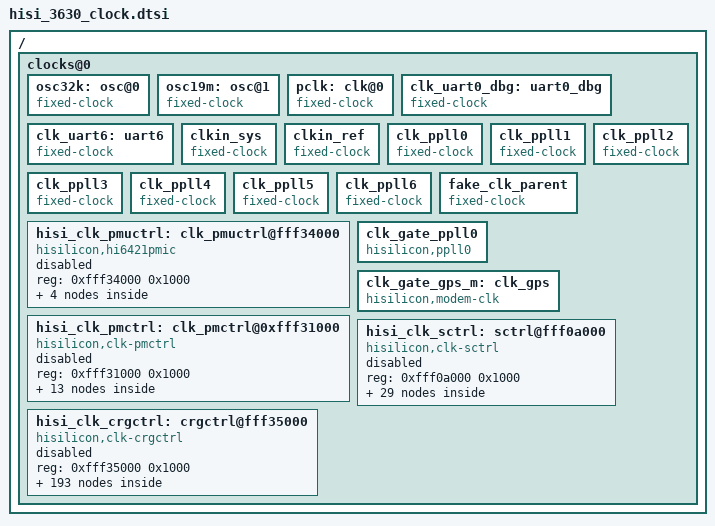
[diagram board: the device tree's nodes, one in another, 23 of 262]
/*
 * Hisilicon Ltd. Hi3630ASIC SoC
 *
 * Copyright (C) 2013 Hisilicon Technologies CO., Ltd.
 *
 * This program is free software; you can redistribute it and/or modify
 * it under the terms of the GNU General Public License version 2 as
 * publishhed by the Free Software Foundation.
 */
/ {
	clocks@0 {

		#address-cells = <1>;
		#size-cells = <1>;
		ranges;

		/*------------fixed clock---------------*/
		osc32k: osc@0 {
			compatible = "fixed-clock";
			#clock-cells = <0>;
			clock-frequency = <32768>;
			clock-output-names = "osc32khz";
		};

		osc19m: osc@1 {
			compatible = "fixed-clock";
			#clock-cells = <0>;
			clock-frequency = <19200000>;
			clock-output-names = "osc19mhz";
		};

		pclk: clk@0 {
			compatible = "fixed-clock";
			#clock-cells = <0>;
			clock-frequency = <20000000>;
			clock-output-names = "apb_pclk";
		};

		clk_uart0_dbg: uart0_dbg {
                        compatible = "fixed-clock";
                        #clock-cells = <0>;
                        clock-frequency = <19200000>;
                        clock-output-names = "uart0clk_dbg";
                };

		clk_uart6: uart6 {
			compatible = "fixed-clock";
			#clock-cells = <0>;
			clock-frequency = <19200000>;
			clock-output-names = "uart6clk";
		};

		clkin_sys: clkin_sys {
			compatible = "fixed-clock";
			#clock-cells = <0>;
			clock-frequency = <19200000>;
			clock-output-names = "clkin_sys";
		};

		clkin_ref: clkin_ref {
			compatible = "fixed-clock";
			#clock-cells = <0>;
			clock-frequency = <32768>;
			clock-output-names = "clkin_ref";
		};

		clk_ppll0: clk_ppll0 {
			compatible = "fixed-clock";
			#clock-cells = <0>;
			clock-frequency = <1440000000>;
			clock-output-names = "clk_ppll0";
		};

		clk_ppll1: clk_ppll1 {
			compatible = "fixed-clock";
			#clock-cells = <0>;
			clock-frequency = <1440000000>;
			clock-output-names = "clk_ppll1";
		};

		clk_ppll2: clk_ppll2 {
			compatible = "fixed-clock";
			#clock-cells = <0>;
			clock-frequency = <594000000>;
			clock-output-names = "clk_ppll2";
		};

		clk_ppll3: clk_ppll3 {
			compatible = "fixed-clock";
			#clock-cells = <0>;
			clock-frequency = <1600000000>;
			clock-output-names = "clk_ppll3";
		};

		clk_ppll4: clk_ppll4 {
			compatible = "fixed-clock";
			#clock-cells = <0>;
			clock-frequency = <667000000>;
			clock-output-names = "clk_ppll4";
		};

		clk_ppll5: clk_ppll5 {
			compatible = "fixed-clock";
			#clock-cells = <0>;
			clock-frequency = <420000000>;
			clock-output-names = "clk_ppll5";
		};

		clk_ppll6: clk_ppll6 {
			compatible = "fixed-clock";
			#clock-cells = <0>;
			clock-frequency = <491520000>;
			clock-output-names = "clk_ppll6";
		};

		fake_clk_parent: fake_clk_parent {
			compatible = "fixed-clock";
			#clock-cells = <0>;
			clock-frequency = <1000000>;
			clock-output-names = "fake_clk_parent";
		};

		hisi_clk_pmuctrl: clk_pmuctrl@fff34000 {
			compatible = "hisilicon,hi6421pmic";
			reg = <0xfff34000 0x1000>;
			status = "disabled";

			clk_pmu32ka: pmu32ka {
				compatible = "hisilicon,clk-gate";
				#clock-cells = <0>;
				pmu32khz;
				clocks = <&clkin_ref>;
				hisilicon,clkgate = <0xf0 0>;
				clock-output-names = "clk_pmu32ka";
			};

			clk_pmu32kb: pmu32kb {
				compatible = "hisilicon,clk-gate";
				#clock-cells = <0>;
				pmu32khz;
				clocks = <&clkin_ref>;
				hisilicon,clkgate = <0xf0 1>;
				clock-output-names = "clk_pmu32kb";
			};

			clk_pmu32kc: pmu32kc {
				compatible = "hisilicon,clk-gate";
				#clock-cells = <0>;
				pmu32khz;
				clocks = <&clkin_ref>;
				hisilicon,clkgate = <0xf0 2>;
				clock-output-names = "clk_pmu32kc";
			};

			clk_pmuaudioclk: clk_pmuaudioclk {
				compatible = "hisilicon,clk-gate";
				#clock-cells = <0>;
				pmu32khz;
				clocks = <&clkin_sys>;
				hisilicon,clkgate = <0xe6 7>;
				clock-output-names = "clk_pmuaudioclk";
			};

		};

		clk_gate_ppll0: clk_gate_ppll0 {
			compatible = "hisilicon,ppll0";
			#clock-cells = <0>;
			clocks = <&clk_ppll0>;
			hisilicon,ipc-lpm3-cmd = <0x000D0102 0x0>;
			clock-output-names = "clk_ap_ppll0";
		};

		clk_gate_gps_m:clk_gps {
			compatible = "hisilicon,modem-clk";
                        #clock-cells = <0>;
                        clocks = <&clkin_sys>;
			hisilicon,ipc-lpm3-cmd-en = <0x000D0002 0x7>;
			hisilicon,ipc-lpm3-cmd-dis = <0x000D0102 0x7>;
                        clock-output-names = "clk_gps";

		};

		hisi_clk_pmctrl: clk_pmctrl@0xfff31000 {
			compatible = "hisilicon,clk-pmctrl";
			reg = <0xfff31000 0x1000>;
			status = "disabled";

			clk_gate_ppll2: clk_gate_ppll2 {
				compatible = "hisilicon,ppll2";
				#clock-cells = <0>;
				clocks = <&clk_ppll2>;
				hisilicon,ppll2-powerdown = <0x40 0 26>;
				hisilicon,ppll2-gateen = <0x44 1 26>;
				clock-output-names = "clk_hdmi_ppll2";
			};

			/* A15 */
			clk_cluster0: clk_cluster0 {
				compatible = "hisilicon,hi3630-xfreq-clk";
				#clock-cells = <0>;
				hisilicon,get-rate-ipc-cmd = <0x0001020A 0x0>;
				hisilicon,set-rate-ipc-cmd = <0x0001030A 0x0>;
				/* <offset, mask_bits> */
				hisilicon,pll-sel = <0x164 0x3>;
				hisilicon,pll-div = <0x0 0x0 0x0 0x0>;
				hisilicon,hi3630-xfreq-devid = <0>;
				clock-output-names = "cpu-cluster.0";
			};

			/* A7 */
			clk_cluster1: clk_cluster1 {
				compatible = "hisilicon,hi3630-xfreq-clk";
				#clock-cells = <0>;
				hisilicon,get-rate-ipc-cmd = <0x0002020A 0x0>;
				hisilicon,set-rate-ipc-cmd = <0x0002030A 0x0>;
				/* <offset, mask_bits> */
				hisilicon,pll-sel = <0xA4 0x3>;
				hisilicon,pll-div = <0x0 0x0 0x0 0x0>;
				hisilicon,hi3630-xfreq-devid = <1>;
				clock-output-names = "cpu-cluster.1";
			};

			clk_g3d: clk_g3d {
				compatible = "hisilicon,hi3630-xfreq-clk";
				#clock-cells = <0>;
				hisilicon,get-rate-ipc-cmd = <0x0003020A 0x0>;
				hisilicon,set-rate-ipc-cmd = <0x0003030A 0x0>;
				/* <offset, mask_bits> */
				hisilicon,pll-sel = <0x0 0x0>;
				hisilicon,pll-div = <0x0 0x0 0x0 0x0>;
				hisilicon,hi3630-xfreq-devid = <2>;
				clock-output-names = "clk_g3d";
			};

			clk_ddrc_freq: clk_ddrc_freq {
				compatible = "hisilicon,hi3630-xfreq-clk";
				#clock-cells = <0>;
				hisilicon,get-rate-ipc-cmd = <0x0004020A 0x0>;
				hisilicon,set-rate-ipc-cmd = <0x00040309 0x0>;
				/* <offset, mask_bits> */
				hisilicon,pll-sel = <0x300 0xf0>;
				/* <offset ddrc_clk_divmask ddrc_aclk_divmask ddrc_busclk_divmask> */
				hisilicon,pll-div = <0x308 0x1f 0x60 0x180>;
				hisilicon,hi3630-xfreq-devid = <3>;
				clock-output-names = "clk_ddrc_freq";
			};

			clk_ddrc_min: clk_ddrc_min {
                                compatible = "hisilicon,hi3630-xfreq-clk";
                                #clock-cells = <0>;
                                hisilicon,get-rate-ipc-cmd = <0x0004020A 0x0>;
                                hisilicon,set-rate-ipc-cmd = <0x00040309 0x0>;
                                /* <offset, mask_bits> */
                                hisilicon,pll-sel = <0x300 0xf0>;
                                /* <offset ddrc_clk_divmask ddrc_aclk_divmask ddrc_busclk_divmask> */
                                hisilicon,pll-div = <0x308 0x1f 0x60 0x180>;
                                hisilicon,hi3630-xfreq-devid = <4>;
                                clock-output-names = "clk_ddrc_min";
                        };

			clk_ddrc_max: clk_ddrc_max {
				compatible = "hisilicon,hi3630-xfreq-clk";
				#clock-cells = <0>;
				hisilicon,get-rate-ipc-cmd = <0x0004020A 0x0>;
				hisilicon,set-rate-ipc-cmd = <0x00040308 0x0>;
				/* <offset, mask_bits> */
				hisilicon,pll-sel = <0x300 0xf0>;
				/* <offset ddrc_clk_divmask ddrc_aclk_divmask ddrc_busclk_divmask> */
				hisilicon,pll-div = <0x308 0x1f 0x60 0x180>;
				hisilicon,hi3630-xfreq-devid = <5>;
				clock-output-names = "clk_ddrc_max";
			};

			clk_xfreq_ppll1: clk_xfreq_ppll1 {
				compatible = "hisilicon,hi3630-xfreq-pll";
				#clock-cells = <0>;
				hisilicon,pll-ctrl-reg = <0x38>;
				clock-output-names = "ddrc_ppll1";
			};

			clk_xfreq_ppll2: clk_xfreq_ppll2 {
				compatible = "hisilicon,hi3630-xfreq-pll";
				#clock-cells = <0>;
				hisilicon,pll-ctrl-reg = <0x40>;
				clock-output-names = "ddrc_ppll2";
			};

			clk_xfreq_ppll3: clk_xfreq_ppll3 {
				compatible = "hisilicon,hi3630-xfreq-pll";
				#clock-cells = <0>;
				hisilicon,pll-ctrl-reg = <0x48>;
				clock-output-names = "ddrc_ppll3";
			};

			clk_xfreq_appll0: clk_xfreq_appll0 {
				compatible = "hisilicon,hi3630-xfreq-pll";
				#clock-cells = <0>;
				hisilicon,pll-ctrl-reg = <0x10>;
				clock-output-names = "clk_appll0";
			};

			clk_xfreq_appll1: clk_xfreq_appll1 {
				compatible = "hisilicon,hi3630-xfreq-pll";
				#clock-cells = <0>;
				hisilicon,pll-ctrl-reg = <0x18>;
				clock-output-names = "clk_appll1";
			};

			clk_xfreq_appll2: clk_xfreq_appll2 {
				compatible = "hisilicon,hi3630-xfreq-pll";
				#clock-cells = <0>;
				hisilicon,pll-ctrl-reg = <0x20>;
				clock-output-names = "clk_appll2";
			};
		};

		hisi_clk_sctrl: sctrl@fff0a000 {
			compatible = "hisilicon,clk-sctrl";
			reg = <0xfff0a000 0x1000>;
			status = "disabled";

			clk_xfreq_ppll0: clk_xfreq_ppll0 {
				compatible = "hisilicon,hi3630-xfreq-pll";
				#clock-cells = <0>;
				hisilicon,pll-ctrl-reg = <0x20>;
				clock-output-names = "ddrc_ppll0";
			};

			/*---------------------SYS TIMER CLOCK----------------------*/
			clk_gate_timclk0: clk_timclk0 {
				compatible = "hisilicon,hi3630-clk-gate";
				#clock-cells = <0>;
				clocks = <&clk_mux_timer0>;
				/* <0x0 0x0> reprents the enable reg is fake */
				hisilicon,hi3630-clkgate = <0x0 0x0>;
				clock-output-names = "clk_timclk0";
			};

			clk_gate_timclk1: clk_timclk1 {
				compatible = "hisilicon,hi3630-clk-gate";
				#clock-cells = <0>;
				clocks = <&clk_mux_timer1>;
				/* <0x0 0x0> reprents the enable reg is fake */
				hisilicon,hi3630-clkgate = <0x0 0x0>;
				clock-output-names = "clk_timclk1";
			};

			clk_gate_timclk2: clk_timclk2 {
				compatible = "hisilicon,hi3630-clk-gate";
				#clock-cells = <0>;
				clocks = <&clk_mux_timer2>;
				/* <0x0 0x0> reprents the enable reg is fake */
				hisilicon,hi3630-clkgate = <0x0 0x0>;
				clock-output-names = "clk_timclk2";
			};

			clk_gate_timclk3: clk_timclk3 {
				compatible = "hisilicon,hi3630-clk-gate";
				#clock-cells = <0>;
				clocks = <&clk_mux_timer3>;
				/* <0x0 0x0> reprents the enable reg is fake */
				hisilicon,hi3630-clkgate = <0x0 0x0>;
				clock-output-names = "clk_timclk3";
			};

			clk_mux_timer0: clk_mux_timer0 {
				compatible = "hisilicon,hi3630-clk-mux";
				#clock-cells = <0>;
				clocks = <&clkin_ref &clk_gate_timer01 &pclk &pclk>;
				hisilicon,clkmux-reg = <0 0x600>;
				clock-output-names = "clkmux_timer0";
			};

			clk_mux_timer1: clk_mux_timer1 {
				compatible = "hisilicon,hi3630-clk-mux";
				#clock-cells = <0>;
				clocks = <&clkin_ref &clk_gate_timer23 &pclk &pclk>;
				hisilicon,clkmux-reg = <0 0x1800>;
				clock-output-names = "clkmux_timer1";
			};

			clk_mux_timer2: clk_mux_timer2 {
				compatible = "hisilicon,hi3630-clk-mux";
				#clock-cells = <0>;
				clocks = <&clkin_ref &clk_gate_timer45 &pclk &pclk>;
				hisilicon,clkmux-reg = <0 0x6000>;
				clock-output-names = "clkmux_timer2";
			};

			clk_mux_timer3: clk_mux_timer3 {
				compatible = "hisilicon,hi3630-clk-mux";
				#clock-cells = <0>;
				clocks = <&clkin_ref &clk_gate_timer67 &pclk &pclk>;
				hisilicon,clkmux-reg = <0 0x18000>;
				clock-output-names = "clkmux_timer3";
			};

			clk_gate_timer01: clkgate@32 {
				compatible = "hisilicon,hi3630-clk-gate";
				#clock-cells = <0>;
				clocks = <&clk_factor_tcxo>;
				clock-output-names = "clk_timer01";
				hisilicon,hi3630-clkgate = <0x30 0x18>;
			};

			clk_gate_timer23: clkgate@33 {
				compatible = "hisilicon,hi3630-clk-gate";
				#clock-cells = <0>;
				clocks = <&clk_factor_tcxo>;
				clock-output-names = "clk_timer23";
				hisilicon,hi3630-clkgate = <0x30 0x60>;
			};

			clk_gate_timer45: clkgate@34 {
				compatible = "hisilicon,hi3630-clk-gate";
				#clock-cells = <0>;
				clocks = <&clk_factor_tcxo>;
				clock-output-names = "clk_timer45";
				hisilicon,hi3630-clkgate = <0x30 0x180>;
			};

			clk_gate_timer67: clkgate@35 {
				compatible = "hisilicon,hi3630-clk-gate";
				#clock-cells = <0>;
				clocks = <&clk_factor_tcxo>;
				clock-output-names = "clk_timer67";
				hisilicon,hi3630-clkgate = <0x30 0x600>;
			};

			clk_factor_tcxo: clk_factor_tcxo {
				compatible = "fixed-factor-clock";
				#clock-cells = <0>;
				clocks = <&clkin_sys>;
				/*mult, div*/
				clock-div = <4>;
				clock-mult = <1>;
				clock-output-names = "clk_factor_tcxo";
			};

			/*--------------------------AO GPIO--------------------------*/
			pclk_ao_gpio0: pclk_ao_gpio0 {
				compatible = "hisilicon,hi3630-clk-gate";
				#clock-cells = <0>;
				clocks = <&clk_div_aobus>;
				hisilicon,hi3630-clkgate = <0x30 0x800>;
				clock-output-names = "pclk_ao_gpio0";
			};

			pclk_ao_gpio1: pclk_ao_gpio1 {
				compatible = "hisilicon,hi3630-clk-gate";
				#clock-cells = <0>;
				clocks = <&clk_div_aobus>;
				hisilicon,hi3630-clkgate = <0x30 0x1000>;
				clock-output-names = "pclk_ao_gpio1";
			};

			pclk_ao_gpio2: pclk_ao_gpio2 {
				compatible = "hisilicon,hi3630-clk-gate";
				#clock-cells = <0>;
				clocks = <&clk_div_aobus>;
				hisilicon,hi3630-clkgate = <0x30 0x2000>;
				clock-output-names = "pclk_ao_gpio2";
			};

			pclk_ao_gpio3: pclk_ao_gpio3 {
				compatible = "hisilicon,hi3630-clk-gate";
				#clock-cells = <0>;
				clocks = <&clk_div_aobus>;
				hisilicon,hi3630-clkgate = <0x30 0x4000>;
				clock-output-names = "pclk_ao_gpio3";
			};

			pclk_ao_gpio4: pclk_ao_gpio4 {
				compatible = "hisilicon,hi3630-clk-gate";
				#clock-cells = <0>;
				clocks = <&clk_div_aobus>;
				hisilicon,hi3630-clkgate = <0x30 0x200000>;
				clock-output-names = "pclk_ao_gpio4";
			};

			pclk_ao_gpio5: pclk_ao_gpio5 {
				compatible = "hisilicon,hi3630-clk-gate";
				#clock-cells = <0>;
				clocks = <&clk_div_aobus>;
				hisilicon,hi3630-clkgate = <0x30 0x400000>;
				clock-output-names = "pclk_ao_gpio5";
			};

			/**/
			clk_div_aobus: clk_div_aobus {
				compatible = "hisilicon,hi3630-clk-div";
				#clock-cells = <0>;
				clocks = <&clk_gate_ppll0>;
				hisilicon,clkdiv-table = <64 1>;
				/*divider register offset, bits*/
				hisilicon,clkdiv = <0x104 0x3f>;
				clock-output-names = "clkdiv_aobus";
			};

			pclk_gate_rtc: pclk_rtc {
				compatible = "hisilicon,hi3630-clk-gate";
				#clock-cells = <0>;
				clocks = <&clk_div_aobus>;
				hisilicon,hi3630-clkgate = <0x30 0x2>;
				clock-output-names = "pclk_rtc";
			};

			/* follow timer clock to be another spare case,*/
			/*pclk_timer0: pclk_timer0 {
				compatible = "hisilicon,hi3630-clk-gate";
				#clock-cells = <0>;
				clocks = <&clk_div_aobus>;
				hisilicon,hi3630-clkgate = <0x30 0x8>;
				clock-output-names = "pclk_timer0";
			};*/

			/*clk_timer0: clk_timer0 {
				compatible = "hisilicon,hi3630-clk-gate";
				#clock-cells = <0>;
				clocks = <&clk_div_aobus>;
				hisilicon,hi3630-clkgate = <0x30 0x10>;
				clock-output-names = "clk_timer0";
				clock-friend-names = "pclk_timer0";
			};*/

			/*pclk_timer1: pclk_timer1 {
				compatible = "hisilicon,hi3630-clk-gate";
				#clock-cells = <0>;
				clocks = <&clk_div_aobus>;
				hisilicon,hi3630-clkgate = <0x30 0x20>;
				clock-output-names = "pclk_timer1";
			};*/

			/*clk_timer1: clk_timer1 {
				compatible = "hisilicon,hi3630-clk-gate";
				#clock-cells = <0>;
				clocks = <&clk_div_aobus>;
				hisilicon,hi3630-clkgate = <0x30 0x40>;
				clock-output-names = "clk_timer1";
				clock-friend-names = "pclk_timer1";
			};*/

			/*pclk_timer2: pclk_timer2 {
				compatible = "hisilicon,hi3630-clk-gate";
				#clock-cells = <0>;
				clocks = <&clk_div_aobus>;
				hisilicon,hi3630-clkgate = <0x30 0x80>;
				clock-output-names = "pclk_timer2";
			};*/

			/*clk_timer2: clk_timer2 {
				compatible = "hisilicon,hi3630-clk-gate";
				#clock-cells = <0>;
				clocks = <&clk_div_aobus>;
				hisilicon,hi3630-clkgate = <0x30 0x100>;
				clock-output-names = "clk_timer2";
			};*/

			/*pclk_timer3: pclk_timer3 {
				compatible = "hisilicon,hi3630-clk-gate";
				#clock-cells = <0>;
				clocks = <&clk_div_aobus>;
				hisilicon,hi3630-clkgate = <0x30 0x200>;
				clock-output-names = "pclk_timer3";
			};*/

			/*clk_timer3: clk_timer3 {
				compatible = "hisilicon,hi3630-clk-gate";
				#clock-cells = <0>;
				clocks = <&clk_div_aobus>;
				hisilicon,hi3630-clkgate = <0x30 0x400>;
				clock-output-names = "clk_timer3";
			};*/

			/**/
			clk_gate_out0: clk_gate_out0 {
				compatible = "hisilicon,hi3630-clk-gate";
				#clock-cells = <0>;
				clocks = <&clk_mux_clkout0>;
				hisilicon,hi3630-clkgate = <0x30 0x10000>;
				clock-output-names = "clk_out0";
			};

			clk_gate_out1: clk_gate_out1 {
				compatible = "hisilicon,hi3630-clk-gate";
				#clock-cells = <0>;
				clocks = <&clk_mux_clkout1>;
				hisilicon,hi3630-clkgate = <0x30 0x20000>;
				clock-output-names = "clk_out1";
			};

			clk_div_clkout0_tcxo: clkdiv_out0tcxo {
				compatible = "hisilicon,hi3630-clk-div";
				#clock-cells = <0>;
				clocks = <&clkin_sys>;
				hisilicon,clkdiv-table = <8 1>;
				/*divider register offset, bits*/
				hisilicon,clkdiv = <0x104 0x1c0>;
				clock-output-names = "clkdiv_out0tcxo";
			};

			clk_div_clkout1_tcxo: clkdiv_out1tcxo {
				compatible = "hisilicon,hi3630-clk-div";
				#clock-cells = <0>;
				clocks = <&clkin_sys>;
				hisilicon,clkdiv-table = <8 1>;
				hisilicon,clkdiv = <0x104 0xe00>;
				clock-output-names = "clkdiv_out1tcxo";
			};

			clk_mux_clkout0: clkmux_clkout0 {
				compatible = "hisilicon,hi3630-clk-mux";
				#clock-cells = <0>;
				hiword;
				clocks = <&clkin_ref &clk_div_clkout0_tcxo &clk_div_clkout0_pll &clk_div_clkout0_pll>;
				hisilicon,clkmux-reg = <0x104 0x3000>;
				clock-output-names = "clkmux_clkout0";
			};

			clk_mux_clkout1: clkmux_clkout1 {
				compatible = "hisilicon,hi3630-clk-mux";
				#clock-cells = <0>;
				hiword;
				clocks = <&clkin_ref &clk_div_clkout1_tcxo &clk_div_clkout1_pll &clk_div_clkout1_pll>;
				hisilicon,clkmux-reg = <0x104 0xc000>;
				clock-output-names = "clkmux_clkout1";
			};

			clk_gate_asp_tcxo: clk_asp_tcxo {
				compatible = "hisilicon,hi3630-clk-gate";
				#clock-cells = <0>;
				clocks = <&clkin_sys>;
				hisilicon,hi3630-clkgate = <0x30 0x8000000>;
				clock-output-names = "clk_asp_tcxo";
			};

		};
		hisi_clk_crgctrl: crgctrl@fff35000 {
			compatible = "hisilicon,clk-crgctrl";
			reg = <0xfff35000 0x1000>;
			status = "disabled";

			/*-----------------CRG TIMER CLOCK--------------------*/
			clk_gate_timclk4: clk_timclk4{
				compatible = "hisilicon,hi3630-clk-gate";
				#clock-cells = <0>;
				clocks = <&clk_mux_timer4>;
				/* <0x0 0x0> reprents the enable reg is fake */
				hisilicon,hi3630-clkgate = <0x0 0x0>;
				clock-output-names = "clk_timclk4";
			};

			clk_gate_timclk5: clk_timclk5{
				compatible = "hisilicon,hi3630-clk-gate";
				#clock-cells = <0>;
				clocks = <&clk_mux_timer5>;
				/* <0x0 0x0> reprents the enable reg is fake */
				hisilicon,hi3630-clkgate = <0x0 0x0>;
				clock-output-names = "clk_timclk5";
			};

			clk_gate_timclk6: clk_timclk6{
				compatible = "hisilicon,hi3630-clk-gate";
				#clock-cells = <0>;
				clocks = <&clk_mux_timer6>;
				/* <0x0 0x0> reprents the enable reg is fake */
				hisilicon,hi3630-clkgate = <0x0 0x0>;
				clock-output-names = "clk_timclk6";
			};

			clk_gate_timclk7: clk_timclk7{
				compatible = "hisilicon,hi3630-clk-gate";
				#clock-cells = <0>;
				clocks = <&clk_mux_timer7>;
				/* <0x0 0x0> reprents the enable reg is fake */
				hisilicon,hi3630-clkgate = <0x0 0x0>;
				clock-output-names = "clk_timclk7";
			};

			clk_mux_timer4: clk_mux_timer4 {
				compatible = "hisilicon,hi3630-clk-mux";
				#clock-cells = <0>;
				clocks = <&clkin_ref &clk_gate_timer89 &pclk &pclk>;
				hisilicon,clkmux-reg = <0x140 0x3>;
				clock-output-names = "clkmux_timer4";
			};

			clk_mux_timer5: clk_mux_timer5 {
				compatible = "hisilicon,hi3630-clk-mux";
				#clock-cells = <0>;
				clocks = <&clkin_ref &clk_gate_timer1011 &pclk &pclk>;
				hisilicon,clkmux-reg = <0x140 0xc>;
				clock-output-names = "clkmux_timer5";
			};

			clk_mux_timer6: clk_mux_timer6 {
				compatible = "hisilicon,hi3630-clk-mux";
				#clock-cells = <0>;
				clocks = <&clkin_ref &clk_gate_timer1213 &pclk &pclk>;
				hisilicon,clkmux-reg = <0x140 0x30>;
				clock-output-names = "clkmux_timer6";
			};

			clk_mux_timer7: clk_mux_timer7 {
				compatible = "hisilicon,hi3630-clk-mux";
				#clock-cells = <0>;
				clocks = <&clkin_ref &clk_gate_timer1415 &pclk &pclk>;
				hisilicon,clkmux-reg = <0x140 0xc0>;
				clock-output-names = "clkmux_timer7";
			};

			clk_gate_timer89: clkgate@36 {
				compatible = "hisilicon,hi3630-clk-gate";
				#clock-cells = <0>;
				clocks = <&clk_factor_tcxo>;
				clock-output-names = "clk_timer89";
				hisilicon,hi3630-clkgate = <0x10 0x400000>;
			};

			clk_gate_timer1011: clkgate@37 {
				compatible = "hisilicon,hi3630-clk-gate";
				#clock-cells = <0>;
				clocks = <&clk_factor_tcxo>;
				clock-output-names = "clk_timer1011";
				hisilicon,hi3630-clkgate = <0x10 0x800000>;
			};

			clk_gate_timer1213: clkgate@38 {
				compatible = "hisilicon,hi3630-clk-gate";
				#clock-cells = <0>;
				clocks = <&clk_factor_tcxo>;
				clock-output-names = "clk_timer1213";
				hisilicon,hi3630-clkgate = <0x10 0x1000000>;
			};

			clk_gate_timer1415: clkgate@39 {
				compatible = "hisilicon,hi3630-clk-gate";
				#clock-cells = <0>;
				clocks = <&clk_factor_tcxo>;
				clock-output-names = "clk_timer1415";
				hisilicon,hi3630-clkgate = <0x10 0x2000000>;
			};

			/*------------------------I2C CLOCK------------------------*/
			clk_gate_i2c0: clk_i2c0 {
				compatible = "hisilicon,hi3630-clk-gate";
				#clock-cells = <0>;
				clocks = <&clk_mux_i2c>;
				hisilicon,hi3630-clkgate = <0x20 0x10>;
				clock-output-names = "clk_i2c0";
			};

			clk_gate_i2c1: clk_i2c1 {
				compatible = "hisilicon,hi3630-clk-gate";
				#clock-cells = <0>;
				clocks = <&clk_mux_i2c>;
				hisilicon,hi3630-clkgate = <0x20 0x20>;
				clock-output-names = "clk_i2c1";
			};

			clk_gate_i2c2: clk_i2c2 {
				compatible = "hisilicon,hi3630-clk-gate";
				#clock-cells = <0>;
				clocks = <&clk_mux_i2c>;
				hisilicon,hi3630-clkgate = <0x20 0x40>;
				clock-output-names = "clk_i2c2";
			};

			clk_gate_i2c3: clk_i2c3 {
				compatible = "hisilicon,hi3630-clk-gate";
				#clock-cells = <0>;
				clocks = <&clk_mux_i2c>;
				hisilicon,hi3630-clkgate = <0x20 0x80>;
				clock-output-names = "clk_i2c3";
			};

			clk_gate_i2c4: clk_i2c4 {
				compatible = "hisilicon,hi3630-clk-gate";
				#clock-cells = <0>;
				clocks = <&clk_mux_i2c>;
				hisilicon,hi3630-clkgate = <0x20 0x8000000>;
				clock-output-names = "clk_i2c4";
			};

			clk_div_i2c: clkdiv_i2c {
				compatible = "hisilicon,hi3630-clk-div";
				#clock-cells = <0>;
				clocks = <&clk_div_hsic>;
				hisilicon,clkdiv-table = <16 1>;
				hisilicon,clkdiv = <0xe8 0xf0>;
				clock-output-names = "clkdiv_i2c";
			};

			clk_mux_i2c: clkmux_i2c {
				compatible = "hisilicon,hi3630-clk-mux";
				#clock-cells = <0>;
				hiword;
				clocks = <&clkin_sys &clk_div_i2c>;
				/*select register offset, mask*/
				hisilicon,clkmux-reg = <0xac 0x2000>;
				clock-output-names = "clkmux_i2c";
			};

			/*clk_andgt_i2c: clkgt_i2c {
				compatible = "hisilicon,clk-gate";
				#clock-cells = <0>;
				hiword;
				clocks = <&clk_div_hsic>;
				hisilicon,clkgate = <0xf8 0>;
				clock-output-names = "clkgt_i2c";
			};*/

			/*-------------------------SPI CLOCK----------------------*/
			clk_gate_spi0: clk_spi0 {
				compatible = "hisilicon,hi3630-clk-gate";
				#clock-cells = <0>;
				clocks = <&clk_mux_spi>;
				hisilicon,hi3630-clkgate = <0x20 0x100>;
				clock-output-names = "clk_spi0";
			};

			clk_gate_spi1: clk_gate_spi1 {
				compatible = "hisilicon,hi3630-clk-gate";
				#clock-cells = <0>;
				clocks = <&clk_mux_spi>;
				hisilicon,hi3630-clkgate = <0x20 0x200>;
				clock-output-names = "clk_spi1";
			};

			clk_mux_spi: clkmux_spi {
				compatible = "hisilicon,hi3630-clk-mux";
				#clock-cells = <0>;
				hiword;
				clocks = <&clkin_sys &clk_div_spi>;
				/*select register offset, mask*/
				hisilicon,clkmux-reg = <0xac 0x100>;
				clock-output-names = "clkmux_spi";
			};

			clk_div_spi: clk_div_spi {
				compatible = "hisilicon,hi3630-clk-div";
				#clock-cells = <0>;
				clocks = <&clk_andgt_spi>;
				hisilicon,clkdiv-table = <16 1>;
				hisilicon,clkdiv = <0xc4 0xf000>;
				clock-output-names = "clkdiv_spi";
			};

			clk_andgt_spi: clkgt_spi {
				compatible = "hisilicon,clk-gate";
				#clock-cells = <0>;
				hiword;
				clocks = <&clk_div_hsic>;
				/*enable register, enable bit*/
				hisilicon,clkgate = <0xf4 13>;
				clock-output-names = "clkgt_spi";
			};

			clk_div_hsic: clkdiv_hsic {
				compatible = "hisilicon,hi3630-clk-div";
				#clock-cells = <0>;
				clocks = <&clk_gate_ppll0>;
				hisilicon,clkdiv-table = <4 1>;
				hisilicon,clkdiv = <0xd4 0x180>;
				clock-output-names = "clkdiv_hsic";
			};

			/*clk_andgt_hsic: clkgt_hsic {
				compatible = "hisilicon,clk-gate";
				#clock-cells = <0>;
				hiword;
				clocks = <&clk_gate_ppll0>;
				hisilicon,clkgate = <0xf4 7>;
				clock-output-names = "clkgt_hsic";
			};*/

			/*-----------------------UART CLOCK-----------------------*/
			clk_gate_uart0: clk_uart0 {
				compatible = "hisilicon,hi3630-clk-gate";
				#clock-cells = <0>;
				clocks = <&clk_mux_uartl>;
				hisilicon,hi3630-clkgate = <0x20 0x400>;
				clock-output-names = "clk_uart0";
			};

			clk_gate_uart1: clk_uart1 {
				compatible = "hisilicon,hi3630-clk-gate";
				#clock-cells = <0>;
				clocks = <&clk_mux_uarth>;
				hisilicon,hi3630-clkgate = <0x20 0x800>;
				clock-output-names = "clk_uart1";
			};

			clk_gate_uart2: clk_uart2 {
				compatible = "hisilicon,hi3630-clk-gate";
				#clock-cells = <0>;
				clocks = <&clk_mux_uartl>;
				hisilicon,hi3630-clkgate = <0x20 0x1000>;
				clock-output-names = "clk_uart2";
			};

			clk_gate_uart3: clk_uart3 {
				compatible = "hisilicon,hi3630-clk-gate";
				#clock-cells = <0>;
				clocks = <&clk_mux_uartl>;
				hisilicon,hi3630-clkgate = <0x20 0x2000>;
				clock-output-names = "clk_uart3";
			};

			clk_gate_uart4: clk_uart4 {
				compatible = "hisilicon,hi3630-clk-gate";
				#clock-cells = <0>;
				clocks = <&clk_mux_uarth>;
				hisilicon,hi3630-clkgate = <0x20 0x4000>;
				clock-output-names = "clk_uart4";
			};

			clk_gate_uart5: clk_uart5 {
				compatible = "hisilicon,hi3630-clk-gate";
				#clock-cells = <0>;
				clocks = <&clk_mux_uartl>;
				hisilicon,hi3630-clkgate = <0x20 0x8000>;
				clock-output-names = "clk_uart5";
			};

			clk_mux_uartl: clkmux_uartl {
				compatible = "hisilicon,hi3630-clk-mux";
				#clock-cells = <0>;
				hiword;
				clocks = <&clkin_sys &clk_div_uartl>;
				/*select register offset, mask*/
				hisilicon,clkmux-reg = <0xac 0x4>;
				clock-output-names = "clkmux_uartl";
			};

			clk_mux_uarth: clkmux_uarth {
				compatible = "hisilicon,hi3630-clk-mux";
				#clock-cells = <0>;
				hiword;
				clocks = <&clkin_sys &clk_div_uarth>;
				/*select register offset, mask*/
				hisilicon,clkmux-reg = <0xac 0x8>;
				clock-output-names = "clkmux_uarth";
			};

			clk_div_uarth: clkdiv_uarth {
				compatible = "hisilicon,hi3630-clk-div";
				#clock-cells = <0>;
				clocks = <&clk_andgt_uarth>;
				hisilicon,clkdiv-table = <16 1>;
				hisilicon,clkdiv = <0xb0 0x780>;
				clock-output-names = "clkdiv_uarth";
			};

			clk_div_uartl: clkdiv_uartl {
				compatible = "hisilicon,hi3630-clk-div";
				#clock-cells = <0>;
				clocks = <&clk_andgt_uartl>;
				hisilicon,clkdiv-table = <16 1>;
				hisilicon,clkdiv = <0xb0 0x7800>;
				clock-output-names = "clkdiv_uartl";
			};

			clk_andgt_uarth: clkgt_uarth {
				compatible = "hisilicon,clk-gate";
				#clock-cells = <0>;
				hiword;
				clocks = <&clk_div_hsic>;
				/*enable register, enable bit*/
				hisilicon,clkgate = <0xf4 11>;
				clock-output-names = "clkgt_uarth";
			};

			clk_andgt_uartl: clkgt_uartl {
				compatible = "hisilicon,clk-gate";
				#clock-cells = <0>;
				hiword;
				clocks = <&clk_div_hsic>;
				/*enable register, enable bit*/
				hisilicon,clkgate = <0xf4 12>;
				clock-output-names = "clkgt_uartl";
			};

			/*-----------------------DMA CLOCK----------------------*/
			clk_gate_dmabus: clk_dmabus {
				compatible = "hisilicon,hi3630-clk-gate";
				#clock-cells = <0>;
				clocks = <&clk_div_dmabus>;
				hisilicon,hi3630-clkgate = <0x00 0x400000>;
				clock-output-names = "clk_dmabus";
			};

			clk_gate_dma2cfgbus: clk_dma2cfgbus {
				compatible = "hisilicon,hi3630-clk-gate";
				#clock-cells = <0>;
				clocks = <&clk_div_dmabus>;
				hisilicon,hi3630-clkgate = <0x00 0x800000>;
				clock-output-names = "clk_dma2cfgbus";
			};

			clk_gate_dmac: clk_dmac {
				compatible = "hisilicon,hi3630-clk-gate";
				#clock-cells = <0>;
				clocks = <&clk_div_dmabus>;
				hisilicon,hi3630-clkgate = <0x30 0x1>;
				clock-output-names = "clk_dmac";
			};

			clk_div_dmabus: clkdiv_dmabus {
				compatible = "hisilicon,hi3630-clk-div";
				#clock-cells = <0>;
				clocks = <&clk_div_sysbus>;
				hisilicon,clkdiv-table = <2 1>;
				hisilicon,clkdiv = <0xec 0x8000>;
				clock-output-names = "clkdiv_dmabus";
			};

			clk_div_sysbus: clkdiv_sysbus{
				compatible = "hisilicon,hi3630-clk-div";
				#clock-cells = <0>;
				clocks = <&clk_mux_sysbus>;
				hisilicon,clkdiv-table = <32 1>;
				/*divider register offset, bits*/
				hisilicon,clkdiv = <0xa8 0x1f>;
				clock-output-names = "clkdiv_sysbus";
			};

			clk_mux_sysbus: clkmux_sysbus {
				compatible = "hisilicon,hi3630-clk-mux";
				#clock-cells = <0>;
				hiword;
				clocks = <&clk_gate_ppll0 &clk_ppll1>;
				/*select register offset, mask*/
				hisilicon,clkmux-reg = <0xac 0x1>;
				clock-output-names = "clkmux_sysbus";
			};

			/*-----------------------------GPIO-------------------------*/
			pclk_gpio0: pclk_gpio0 {
				compatible = "hisilicon,hi3630-clk-gate";
				#clock-cells = <0>;
				clocks = <&clk_div_cfgbus>;
				hisilicon,hi3630-clkgate = <0x010 0x1>;
				clock-output-names = "pclk_gpio0";
			};

			pclk_gpio1: pclk_gpio1 {
				compatible = "hisilicon,hi3630-clk-gate";
				#clock-cells = <0>;
				clocks = <&clk_div_cfgbus>;
				hisilicon,hi3630-clkgate = <0x010 0x2>;
				clock-output-names = "pclk_gpio1";
			};

			pclk_gpio2: pclk_gpio2 {
				compatible = "hisilicon,hi3630-clk-gate";
				#clock-cells = <0>;
				clocks = <&clk_div_cfgbus>;
				hisilicon,hi3630-clkgate = <0x010 0x4>;
				clock-output-names = "pclk_gpio2";
			};

			pclk_gpio3: pclk_gpio3 {
				compatible = "hisilicon,hi3630-clk-gate";
				#clock-cells = <0>;
				clocks = <&clk_div_cfgbus>;
				hisilicon,hi3630-clkgate = <0x010 0x8>;
				clock-output-names = "pclk_gpio3";
			};

			pclk_gpio4: pclk_gpio4 {
				compatible = "hisilicon,hi3630-clk-gate";
				#clock-cells = <0>;
				clocks = <&clk_div_cfgbus>;
				hisilicon,hi3630-clkgate = <0x010 0x10>;
				clock-output-names = "pclk_gpio4";
			};

			pclk_gpio5: pclk_gpio5 {
				compatible = "hisilicon,hi3630-clk-gate";
				#clock-cells = <0>;
				clocks = <&clk_div_cfgbus>;
				hisilicon,hi3630-clkgate = <0x010 0x20>;
				clock-output-names = "pclk_gpio5";
			};

			pclk_gpio6: pclk_gpio6 {
				compatible = "hisilicon,hi3630-clk-gate";
				#clock-cells = <0>;
				clocks = <&clk_div_cfgbus>;
				hisilicon,hi3630-clkgate = <0x10 0x40>;
				clock-output-names = "pclk_gpio6";
			};

			pclk_gpio7: pclk_gpio7 {
				compatible = "hisilicon,hi3630-clk-gate";
				#clock-cells = <0>;
				clocks = <&clk_div_cfgbus>;
				hisilicon,hi3630-clkgate = <0x10 0x80>;
				clock-output-names = "pclk_gpio7";
			};

			pclk_gpio8: pclk_gpio8 {
				compatible = "hisilicon,hi3630-clk-gate";
				#clock-cells = <0>;
				clocks = <&clk_div_cfgbus>;
				hisilicon,hi3630-clkgate = <0x10 0x100>;
				clock-output-names = "pclk_gpio8";
			};

			pclk_gpio9: pclk_gpio9 {
				compatible = "hisilicon,hi3630-clk-gate";
				#clock-cells = <0>;
				clocks = <&clk_div_cfgbus>;
				hisilicon,hi3630-clkgate = <0x10 0x200>;
				clock-output-names = "pclk_gpio9";
			};

			pclk_gpio10: pclk_gpio10 {
				compatible = "hisilicon,hi3630-clk-gate";
				#clock-cells = <0>;
				clocks = <&clk_div_cfgbus>;
				hisilicon,hi3630-clkgate = <0x10 0x400>;
				clock-output-names = "pclk_gpio10";
			};

			pclk_gpio11: pclk_gpio11 {
				compatible = "hisilicon,hi3630-clk-gate";
				#clock-cells = <0>;
				clocks = <&clk_div_cfgbus>;
				hisilicon,hi3630-clkgate = <0x10 0x800>;
				clock-output-names = "pclk_gpio11";
			};

			pclk_gpio12: pclk_gpio12 {
				compatible = "hisilicon,hi3630-clk-gate";
				#clock-cells = <0>;
				clocks = <&clk_div_cfgbus>;
				hisilicon,hi3630-clkgate = <0x10 0x1000>;
				clock-output-names = "pclk_gpio12";
			};

			pclk_gpio13: pclk_gpio13 {
				compatible = "hisilicon,hi3630-clk-gate";
				#clock-cells = <0>;
				clocks = <&clk_div_cfgbus>;
				hisilicon,hi3630-clkgate = <0x10 0x2000>;
				clock-output-names = "pclk_gpio13";
			};

			pclk_gpio14: pclk_gpio14 {
				compatible = "hisilicon,hi3630-clk-gate";
				#clock-cells = <0>;
				clocks = <&clk_div_cfgbus>;
				hisilicon,hi3630-clkgate = <0x10 0x4000>;
				clock-output-names = "pclk_gpio14";
			};

			pclk_gpio15: pclk_gpio15 {
				compatible = "hisilicon,hi3630-clk-gate";
				#clock-cells = <0>;
				clocks = <&clk_div_cfgbus>;
				hisilicon,hi3630-clkgate = <0x10 0x8000>;
				clock-output-names = "pclk_gpio15";
			};

			pclk_gpio16: pclk_gpio16 {
				compatible = "hisilicon,hi3630-clk-gate";
				#clock-cells = <0>;
				clocks = <&clk_div_cfgbus>;
				hisilicon,hi3630-clkgate = <0x10 0x10000>;
				clock-output-names = "pclk_gpio16";
			};

			pclk_gpio17: pclk_gpio17 {
				compatible = "hisilicon,hi3630-clk-gate";
				#clock-cells = <0>;
				clocks = <&clk_div_cfgbus>;
				hisilicon,hi3630-clkgate = <0x10 0x20000>;
				clock-output-names = "pclk_gpio17";
			};

			pclk_gpio18: pclk_gpio18 {
				compatible = "hisilicon,hi3630-clk-gate";
				#clock-cells = <0>;
				clocks = <&clk_div_cfgbus>;
				hisilicon,hi3630-clkgate = <0x10 0x40000>;
				clock-output-names = "pclk_gpio18";
			};

			pclk_gpio19: pclk_gpio19 {
				compatible = "hisilicon,hi3630-clk-gate";
				#clock-cells = <0>;
				clocks = <&clk_div_cfgbus>;
				hisilicon,hi3630-clkgate = <0x10 0x80000>;
				clock-output-names = "pclk_gpio19";
			};

			pclk_gpio20: pclk_gpio20 {
				compatible = "hisilicon,hi3630-clk-gate";
				#clock-cells = <0>;
				clocks = <&clk_div_cfgbus>;
				hisilicon,hi3630-clkgate = <0x10 0x100000>;
				clock-output-names = "pclk_gpio20";
			};

			pclk_gpio21: pclk_gpio21 {
				compatible = "hisilicon,hi3630-clk-gate";
				#clock-cells = <0>;
				clocks = <&clk_div_cfgbus>;
				hisilicon,hi3630-clkgate = <0x10 0x200000>;
				clock-output-names = "pclk_gpio21";
			};

			/*------------------------USB CLOCK------------------------*/
			clk_gate_usb2otg_ref: clk_usb2otgref {
				compatible = "hisilicon,hi3630-clk-gate";
				#clock-cells = <0>;
				clocks = <&clk_factor_usbhost12>;
				hisilicon,hi3630-clkgate = <0x40 0x100>;
				clock-output-names = "clk_usb2otgref";
			};

			clk_gate_usb2host_ref: clk_usb2hostref {
				compatible = "hisilicon,hi3630-clk-gate";
				#clock-cells = <0>;
				clocks = <&clk_factor_usbhost12>;
				hisilicon,hi3630-clkgate = <0x40 0x200>;
				clock-output-names = "clk_usb2hostref";
			};

			clk_gate_usbhost12: clk_usbhost12 {
				compatible = "hisilicon,hi3630-clk-gate";
				#clock-cells = <0>;
				clocks = <&clk_factor_usbhost12>;
				hisilicon,hi3630-clkgate = <0x40 0x10>;
				clock-output-names = "clk_usbhost12";
			};

			clk_gate_usbhost48: clk_usbhost48{
				compatible = "hisilicon,hi3630-clk-gate";
				#clock-cells = <0>;
				clocks = <&clk_div_usbhost48>;
				hisilicon,hi3630-clkgate = <0x40 0x8>;
				clock-output-names = "clk_usbhost48";
			};

			clk_factor_usbhost12: clkfac_usbhost {
				compatible = "fixed-factor-clock";
				#clock-cells = <0>;
				clocks = <&clk_div_usbhost48>;
				/*mult, div*/
				clock-div = <4>;
				clock-mult = <1>;
				clock-output-names = "clkfac_usbhost";
			};

			clk_div_usbhost48: clkdiv_usbhost {
				compatible = "hisilicon,hi3630-clk-div";
				#clock-cells = <0>;
				clocks = <&clk_andgt_usbhost48>;
				hisilicon,clkdiv-table = <16 1>;
				hisilicon,clkdiv = <0xd4 0x3c00>;
				clock-output-names = "clkdiv_usbhost";
			};

			clk_andgt_usbhost48: clkgt_usbhost48 {
				compatible = "hisilicon,clk-gate";
				#clock-cells = <0>;
				hiword;
				clocks = <&clk_div_hsic>;
				/*enable register, enable bit*/
				hisilicon,clkgate = <0xf4 8>;
				clock-output-names = "clkgt_usbhost48";
			};

			hclk_gate_usb2otg_pmu: hclk_usb2otgpmu{
				compatible = "hisilicon,hi3630-clk-gate";
				#clock-cells = <0>;
				clocks = <&hclk_div_usb2host>;
				hisilicon,hi3630-clkgate = <0x40 0x1>;
				clock-output-names = "hclk_usb2otgpmu";
			};

			hclk_gate_usb2otg: hclk_usb2otg{
				compatible = "hisilicon,hi3630-clk-gate";
				#clock-cells = <0>;
				clocks = <&hclk_div_usb2host>;
				hisilicon,hi3630-clkgate = <0x40 0x2>;
				clock-output-names = "hclk_usb2otg";
			};

			hclk_gate_usb2host: hclk_usb2host{
				compatible = "hisilicon,hi3630-clk-gate";
				#clock-cells = <0>;
				clocks = <&hclk_div_usb2host>;
				hisilicon,hi3630-clkgate = <0x40 0x4>;
				clock-output-names = "hclk_usb2host";
			};

			clk_gate_usb2hostbus: clk_usb2hostbus{
				compatible = "hisilicon,hi3630-clk-gate";
				#clock-cells = <0>;
				clocks = <&hclk_div_usb2host>;
				hisilicon,hi3630-clkgate = <0x050 0x2>;
				clock-output-names = "clk_usb2hostbus";
			};

			hclk_div_usb2host: hclkdiv_usb2h {
				compatible = "hisilicon,hi3630-clk-div";
				#clock-cells = <0>;
				clocks = <&clk_div_dbgsechsic_bus>;
				hisilicon,clkdiv-table = <4 1>;
				hisilicon,clkdiv = <0xec 0x6000>;
				clock-output-names = "hclkdiv_usb2h";
			};

			clk_div_dbgsechsic_bus: clkdiv_dbgbus {
				compatible = "hisilicon,hi3630-clk-div";
				#clock-cells = <0>;
				clocks = <&clk_div_sysbus>;
				hisilicon,clkdiv-table = <2 1>;
				hisilicon,clkdiv = <0xec 0x1000>;
				clock-output-names = "clkdiv_dbgbus";
			};

			/*-----------------CORESIGHT CLOCK--------------------*/
			/*atclk: clk_at {
				compatible = "hisilicon,clk-gate";
				#clock-cells = <0>;
				clocks = <&clk_div_dbgsechsic_bus>;
				hisilicon,clkgate = <0x128 7>;
				clock-output-names = "clk_at";
			};*/

			/*trackclkin: clk_track {
				compatible = "hisilicon,clk-gate";
				#clock-cells = <0>;
				clocks = <&trackclkin_div>;
				hisilicon,clkgate = <0x128 6>;
				clock-output-names = "clk_track";
			};*/

			atclk: clk_at {
                                compatible = "fixed-factor-clock";
                                #clock-cells = <0>;
                                clocks = <&clk_div_dbgsechsic_bus>;
                                /*mult, div*/
                                clock-div = <1>;
                                clock-mult = <1>;
                                clock-output-names = "clk_at";
                        };

			trackclkin: clk_track {
                                compatible = "fixed-factor-clock";
                                #clock-cells = <0>;
                                clocks = <&trackclkin_div>;
                                /*mult, div*/
                                clock-div = <1>;
                                clock-mult = <1>;
                                clock-output-names = "clk_track";
                        };

			/*pclk_dbg: pclk_dbg {
				compatible = "hisilicon,clk-gate";
				#clock-cells = <0>;
				clocks = <&pclk_div_dbg>;
				hisilicon,clkgate = <0x128 0x2>;
				clock-output-names = "pclk_dbg";
			};*/

			pclk_dbg: pclk_dbg {
                                compatible = "fixed-factor-clock";
                                #clock-cells = <0>;
                                clocks = <&pclk_div_dbg>;
                                /*mult, div*/
                                clock-div = <1>;
                                clock-mult = <1>;
                                clock-output-names = "pclk_dbg";
                        };

			pclk_div_dbg: pclkdiv_dbg {
				compatible = "hisilicon,hi3630-clk-div";
				#clock-cells = <0>;
				clocks = <&clk_div_dbgsechsic_bus>;
				hisilicon,clkdiv-table = <4 1>;
				hisilicon,clkdiv = <0x128 0x1>;
				clock-output-names = "pclkdiv_dbg";
			};

			trackclkin_div: clkdiv_track {
				compatible = "hisilicon,hi3630-clk-div";
				#clock-cells = <0>;
				clocks = <&clk_div_dbgsechsic_bus>;
				hisilicon,clkdiv-table = <4 1>;
				hisilicon,clkdiv = <0x128 0x3000>;
				clock-output-names = "clkdiv_track";
			};

			clk_div_clkout0_pll: clkdiv_out0_pll {
				compatible = "hisilicon,hi3630-clk-div";
				#clock-cells = <0>;
				clocks = <&clk_andgt_out0>;
				hisilicon,clkdiv-table = <64 1>;
				/*divider register offset, bits*/
				hisilicon,clkdiv = <0xe0 0x3f0>;
				clock-output-names = "clkdiv_out0_pll";
			};

			clk_div_clkout1_pll: clkdiv_out1_pll {
				compatible = "hisilicon,hi3630-clk-div";
				#clock-cells = <0>;
				clocks = <&clk_andgt_out1>;
				hisilicon,clkdiv-table = <64 1>;
				/*divider register offset, bits*/
				hisilicon,clkdiv = <0xe0 0xfc00>;
				clock-output-names = "clkdiv_out1_pll";
			};

			clk_andgt_out1: clkgt_out1 {
				compatible = "hisilicon,clk-gate";
				#clock-cells = <0>;
				hiword;
				clocks = <&clk_ppll3>;
				/*enable register, enable bit*/
				hisilicon,clkgate = <0xf0 11>;
				clock-output-names = "clkgt_out1";
			};

			clk_andgt_out0: clkgt_out0 {
				compatible = "hisilicon,clk-gate";
				#clock-cells = <0>;
				hiword;
				clocks = <&clk_ppll3>;
				/*enable register, enable bit*/
				hisilicon,clkgate = <0xf0 10>;
				clock-output-names = "clkgt_out0";
			};

			/*------------------IOMCU CLOCK----------------*/
			/*clk_gate_iomcu: clk_iomcu{
				compatible = "hisilicon,hi3630-clk-gate";
				#clock-cells = <0>;
				clocks = <&clk_div_iomcu>;
				hisilicon,hi3630-clkgate = <0x50 0x200>;
				clock-output-names = "clk_iomcu";
			};*/

			clk_gate_ace2acel: clk_ace2acel{
				compatible = "hisilicon,hi3630-clk-gate";
				#clock-cells = <0>;
				clocks = <&clk_div_iomcu>;
				hisilicon,hi3630-clkgate = <0x50 0x400>;
				clock-output-names = "clk_ace2acel";
			};

			clk_gate_mcpuddr_asyn: clk_mcpuddrasyn{
				compatible = "hisilicon,hi3630-clk-gate";
				#clock-cells = <0>;
				clocks = <&clk_div_iomcu>;
				hisilicon,hi3630-clkgate = <0x50 0x800>;
				clock-output-names = "clk_mcpuddrasyn";
			};

			clk_div_iomcu: clkdiv_iomcu{
				compatible = "hisilicon,hi3630-clk-div";
				#clock-cells = <0>;
				clocks = <&clk_div_sysbus>;
				hisilicon,clkdiv-table = <4 1>;
				hisilicon,clkdiv = <0xa8 0xc00>;
				clock-output-names = "clkdiv_iomcu";
			};

			/*----------------REGULATOR CLOCK----------------*/
			/*ldi*/
			clk_gate_ldi1: clk_ldi1{
				compatible = "hisilicon,hi3630-clk-gate";
				#clock-cells = <0>;
				clocks = <&clk_div_ldi1>;
				hisilicon,hi3630-clkgate = <0x30 0x4000>;
				clock-output-names = "clk_ldi1";
			};

			clk_gate_ldi0: clk_ldi0{
				compatible = "hisilicon,hi3630-clk-gate";
				#clock-cells = <0>;
				clocks = <&clk_div_ldi0>;
				hisilicon,hi3630-clkgate = <0x30 0x8000>;
				clock-output-names = "clk_ldi0";
			};

			clk_div_ldi0: clkdiv_ldi0 {
				compatible = "hisilicon,hi3630-clk-div";
				#clock-cells = <0>;
				clocks = <&clk_andgt_ldi0>;
				hisilicon,clkdiv-table = <64 1>;
				hisilicon,clkdiv = <0xbc 0x3f00>;
				clock-output-names = "clkdiv_ldi0";
			};

			clk_div_ldi1: clkdiv_ldi1 {
				compatible = "hisilicon,hi3630-clk-div";
				#clock-cells = <0>;
				clocks = <&clk_andgt_ldi1>;
				hisilicon,clkdiv-table = <64 1>;
				hisilicon,clkdiv = <0xc0 0x3f00>;
				clock-output-names = "clkdiv_ldi1";
			};

			clk_andgt_ldi0: clkgt_ldi0 {
				compatible = "hisilicon,clk-gate";
				#clock-cells = <0>;
				hiword;
				clocks = <&clk_ppll0>;
				/*enable register, enable bit*/
				hisilicon,clkgate = <0xf0 6>;
				clock-output-names = "clkgt_ldi0";
			};

			clk_andgt_ldi1: clkgt_ldi1 {
				compatible = "hisilicon,clk-gate";
				#clock-cells = <0>;
				hiword;
				clocks = <&clk_mux_ldi1>;
				/*enable register, enable bit*/
				hisilicon,clkgate = <0xf0 7>;
				clock-output-names = "clkgt_ldi1";
			};

			clk_mux_ldi1: clkmux_ldi1 {
				compatible = "hisilicon,hi3630-clk-mux";
				#clock-cells = <0>;
				hiword;
				clocks = <&clk_ppll1 &clk_ppll0 &clk_gate_ppll2 &clk_ppll3>;
				hisilicon,clkmux-reg = <0xc0 0xc000>;
				clock-output-names = "clkmux_ldi1";
			};

			/*dss*/
			pclk_gate_dss: pclk_dss{
				compatible = "hisilicon,hi3630-clk-gate";
				#clock-cells = <0>;
				clocks = <&clk_div_cfgbus>;
				hisilicon,hi3630-clkgate = <0x30 0x1000>;
				clock-output-names = "pclk_dss";
			};

			aclk_gate_dss: aclk_dss{
				compatible = "hisilicon,hi3630-clk-gate";
				#clock-cells = <0>;
				clocks = <&fake_clk_parent>;
				hisilicon,hi3630-clkgate = <0x30 0x2000>;
				clock-output-names = "aclk_dss";
			};

			clk_gate_edc1: clk_edc1{
				compatible = "hisilicon,hi3630-clk-gate";
				#clock-cells = <0>;
				clocks = <&clk_div_edc1>;
				hisilicon,hi3630-clkgate = <0x30 0x10000>;
				clock-output-names = "clk_edc1";
			};

			clk_gate_edc0: clk_edc0{
				compatible = "hisilicon,hi3630-clk-gate";
				#clock-cells = <0>;
				clocks = <&clk_div_edc0>;
				hisilicon,hi3630-clkgate = <0x30 0x20000>;
				clock-output-names = "clk_edc0";
			};

			clk_div_edc1: clkdiv_edc1 {
				compatible = "hisilicon,hi3630-clk-div";
				#clock-cells = <0>;
				clocks = <&clk_andgt_edc1>;
				hisilicon,clkdiv-table = <64 1>;
				hisilicon,clkdiv = <0xc0 0x3f>;
				clock-output-names = "clkdiv_edc1";
			};

			clk_div_edc0: clkdiv_edc0 {
				compatible = "hisilicon,hi3630-clk-div";
				#clock-cells = <0>;
				clocks = <&clk_andgt_edc0>;
				hisilicon,clkdiv-table = <64 1>;
				hisilicon,clkdiv = <0xbc 0x3f>;
				clock-output-names = "clkdiv_edc0";
			};

			clk_andgt_edc0: clkgt_edc0 {
				compatible = "hisilicon,clk-gate";
				#clock-cells = <0>;
				hiword;
				clocks = <&clk_gate_ppll0>;
				/*enable register, enable bit*/
				hisilicon,clkgate = <0xf0 8>;
				clock-output-names = "clkgt_edc0";
			};

			clk_andgt_edc1: clkgt_edc1 {
				compatible = "hisilicon,clk-gate";
				#clock-cells = <0>;
				hiword;
				clocks = <&clk_gate_ppll0>;
				/*enable register, enable bit*/
				hisilicon,clkgate = <0xf0 9>;
				clock-output-names = "clkgt_edc1";
			};

			/*isp*/
			aclk_gate_isp: aclk_isp{
				compatible = "hisilicon,hi3630-clk-gate";
				#clock-cells = <0>;
				clocks = <&fake_clk_parent>;
				hisilicon,hi3630-clkgate = <0x30 0x800000>;
				clock-output-names = "aclk_isp";
			};

			hclk_gate_isp: hclk_isp{
				compatible = "hisilicon,hi3630-clk-gate";
				#clock-cells = <0>;
				clocks = <&clk_div_cfgbus>;
				hisilicon,hi3630-clkgate = <0x30 0x1000000>;
				clock-output-names = "hclk_isp";
			};

			clk_gate_ispmipi: clk_ispmipi{
				compatible = "hisilicon,hi3630-clk-gate";
				#clock-cells = <0>;
				clocks = <&clk_div_ispmipi>;
				hisilicon,hi3630-clkgate = <0x30 0x2000000>;
				clock-output-names = "clk_ispmipi";
			};

			clk_gate_ispmcu: clk_ispmcu{
				compatible = "hisilicon,hi3630-clk-gate";
				#clock-cells = <0>;
				clocks = <&clk_div_ispmcu>;
				hisilicon,hi3630-clkgate = <0x30 0x4000000>;
				clock-output-names = "clk_ispmcu";
			};

			clk_gate_ispcore: clk_ispcore{
				compatible = "hisilicon,hi3630-clk-gate";
				#clock-cells = <0>;
				clocks = <&clk_div_isp>;
				hisilicon,hi3630-clkgate = <0x30 0x8000000>;
				clock-output-names = "clk_ispcore";
			};

			clk_div_ispmipi: clkdiv_ispmipi {
				compatible = "hisilicon,hi3630-clk-div";
				#clock-cells = <0>;
				clocks = <&clk_andgt_ispmipi>;
				hisilicon,clkdiv-table = <32 1>;
				hisilicon,clkdiv = <0xc4 0x1f>;
				clock-output-names = "clkdiv_ispmipi";
			};

			clk_div_isp: clkdiv_isp {
				compatible = "hisilicon,hi3630-clk-div";
				#clock-cells = <0>;
				clocks = <&clk_andgt_isp>;
				hisilicon,clkdiv-table = <32 1>;
				hisilicon,clkdiv = <0xc4 0x7c0>;
				clock-output-names = "clkdiv_isp";
			};

			clk_div_ispmcu: clkdiv_ispmcu {
				compatible = "hisilicon,hi3630-clk-div";
				#clock-cells = <0>;
				clocks = <&clk_andgt_ispmcu>;
				hisilicon,clkdiv-table = <32 1>;
				hisilicon,clkdiv = <0xc8 0x1f>;
				clock-output-names = "clkdiv_ispmcu";
			};

			clk_andgt_isp: clkgt_isp {
				compatible = "hisilicon,clk-gate";
				#clock-cells = <0>;
				hiword;
				clocks = <&clk_gate_ppll0>;
				/*enable register, enable bit*/
				hisilicon,clkgate = <0xf0 12>;
				clock-output-names = "clkgt_isp";
			};

			clk_andgt_ispmipi: clkgt_ispmipi {
				compatible = "hisilicon,clk-gate";
				#clock-cells = <0>;
				hiword;
				clocks = <&clk_gate_ppll0>;
				/*enable register, enable bit*/
				hisilicon,clkgate = <0xf0 13>;
				clock-output-names = "clkgt_ispmipi";
			};

			clk_andgt_ispmcu: clkgt_ispmcu {
				compatible = "hisilicon,clk-gate";
				#clock-cells = <0>;
				hiword;
				clocks = <&clk_gate_ppll0>;
				/*enable register, enable bit*/
				hisilicon,clkgate = <0xf0 14>;
				clock-output-names = "clkgt_ispmcu";
			};

			/*venc*/
			clk_gate_vencbus: clk_vencbus {
				compatible = "hisilicon,hi3630-clk-gate";
				#clock-cells = <0>;
				clocks = <&clk_div_venc>;
				hisilicon,hi3630-clkgate = <0x00 0x40000000>;
				clock-output-names = "clk_vencbus";
			};

			clk_gate_venc: clk_venc{
				compatible = "hisilicon,hi3630-clk-gate";
				#clock-cells = <0>;
				clocks = <&clk_div_venc>;
				hisilicon,hi3630-clkgate = <0x30 0x400>;
				clock-output-names = "clk_venc";
				clock-friend-names = "clk_vencbus";
			};

			clk_div_venc: clkdiv_venc {
				compatible = "hisilicon,hi3630-clk-div";
				#clock-cells = <0>;
				clocks = <&clk_andgt_venc>;
				hisilicon,clkdiv-table = <32 1>;
				hisilicon,clkdiv = <0xc8 0x7c0>;
				clock-output-names = "clkdiv_venc";
			};

			clk_andgt_venc: clkgt_venc {
				compatible = "hisilicon,clk-gate";
				#clock-cells = <0>;
				hiword;
				clocks = <&clk_gate_ppll0>;
				/*enable register, enable bit*/
				hisilicon,clkgate = <0xf4 0>;
				clock-output-names = "clkgt_venc";
			};

			/*vdec*/
			clk_gate_vdecbus: clk_vdecbus {
				compatible = "hisilicon,hi3630-clk-gate";
				#clock-cells = <0>;
				clocks = <&clk_div_vdec>;
				hisilicon,hi3630-clkgate = <0x00 0x20000000>;
				clock-output-names = "clk_vdecbus";
			};

			clk_gate_vdec: clk_vdec{
				compatible = "hisilicon,hi3630-clk-gate";
				#clock-cells = <0>;
				clocks = <&clk_div_vdec>;
				hisilicon,hi3630-clkgate = <0x30 0x800>;
				clock-output-names = "clk_vdec";
				clock-friend-names = "clk_vdecbus";
			};

			clk_div_vdec: clkdiv_vdec {
				compatible = "hisilicon,hi3630-clk-div";
				#clock-cells = <0>;
				clocks = <&clk_andgt_vdec>;
				hisilicon,clkdiv-table = <32 1>;
				hisilicon,clkdiv = <0xcc 0x1f>;
				clock-output-names = "clkdiv_vdec";
			};

			clk_andgt_vdec: clkgt_vdec {
				compatible = "hisilicon,clk-gate";
				#clock-cells = <0>;
				hiword;
				clocks = <&clk_gate_ppll0>;
				/*enable register, enable bit*/
				hisilicon,clkgate = <0xf0 15 >;
				clock-output-names = "clkgt_vdec";
			};

			/*vpp*/
			clk_gate_vppjpegbus: clk_vppjpegbus {
				compatible = "hisilicon,hi3630-clk-gate";
				#clock-cells = <0>;
				clocks = <&clk_div_vpp>;
				hisilicon,hi3630-clkgate = <0x00 0x200000>;
				clock-output-names = "clk_vppjpegbus";
			};

			clk_gate_vppbus: clk_vppbus {
				compatible = "hisilicon,hi3630-clk-gate";
				#clock-cells = <0>;
				clocks = <&clk_div_vpp>;
				hisilicon,hi3630-clkgate = <0x00 0x80000000>;
				clock-output-names = "clk_vppbus";
			};

			clk_gate_vpp: clk_vpp{
				compatible = "hisilicon,hi3630-clk-gate";
				#clock-cells = <0>;
				clocks = <&clk_div_vpp>;
				hisilicon,hi3630-clkgate = <0x30 0x200>;
				clock-output-names = "clk_vpp";
				clock-friend-names = "clk_vppbus";
			};

			clk_div_vpp: clkdiv_vpp {
				compatible = "hisilicon,hi3630-clk-div";
				#clock-cells = <0>;
				clocks = <&clk_andgt_vpp>;
				hisilicon,clkdiv-table = <32 1>;
				hisilicon,clkdiv = <0xcc 0x7c0>;
				clock-output-names = "clkdiv_vpp";
			};

			clk_andgt_vpp: clkgt_vpp {
				compatible = "hisilicon,clk-gate";
				#clock-cells = <0>;
				hiword;
				clocks = <&clk_gate_ppll0>;
				hisilicon,clkgate = <0xf4 1>;
				clock-output-names = "clkgt_vpp";
			};

			/*--------------------EMMC CLOCK------------------------*/
			clk_gate_mmc0: clk_mmc0 {
				compatible = "hisilicon,hi3630-clk-gate";
				#clock-cells = <0>;
				clocks = <&clk_mux_mmc0>;
				hisilicon,hi3630-clkgate = <0x40 0x10000>;
				clock-output-names = "clk_mmc0";
			};

			clk_gate_mmc1: clk_mmc1{
				compatible = "hisilicon,hi3630-clk-gate";
				#clock-cells = <0>;
				clocks = <&clk_div_mmc1>;
				hisilicon,hi3630-clkgate = <0x40 0x20000>;
				clock-output-names = "clk_mmc1";
			};

			clk_gate_mmc2: clk_mmc2{
				compatible = "hisilicon,hi3630-clk-gate";
				#clock-cells = <0>;
				clocks = <&clk_div_mmc2>;
				hisilicon,hi3630-clkgate = <0x40 0x40000>;
				clock-output-names = "clk_mmc2";
			};

			clk_mux_mmc0: clkmux_mmc0 {
				compatible = "hisilicon,hi3630-clk-mux";
				#clock-cells = <0>;
				hiword;
				clocks = <&clkin_sys &clkin_sys &clkin_sys &clkin_sys &clk_div_mmc0 &clk_div_mmc0 &clk_div_mmc0 &clk_div_mmc0>;
				hisilicon,clkmux-reg = <0xb4 0x70>;
				clock-output-names = "clkmux_mmc0";
			};

			clk_div_mmc0: clkdiv_mmc0 {
				compatible = "hisilicon,hi3630-clk-div";
				#clock-cells = <0>;
				clocks = <&clk_andgt_mmc0>;
				hisilicon,clkdiv-table = <16 1>;
				hisilicon,clkdiv = <0xb4 0xf>;
				clock-output-names = "clkdiv_mmc0";
			};

			clk_div_mmc1: clkdiv_mmc1 {
				compatible = "hisilicon,hi3630-clk-div";
				#clock-cells = <0>;
				clocks = <&clk_andgt_mmc1>;
				hisilicon,clkdiv-table = <16 1>;
				hisilicon,clkdiv = <0xb4 0x780>;
				clock-output-names = "clkdiv_mmc1";
			};

			clk_div_mmc2: clkdiv_mmc2 {
				compatible = "hisilicon,hi3630-clk-div";
				#clock-cells = <0>;
				clocks = <&clk_andgt_mmc2>;
				hisilicon,clkdiv-table = <16 1>;
				hisilicon,clkdiv = <0xb8 0xf>;
				clock-output-names = "clkdiv_mmc2";
			};

			clk_andgt_mmc0: clkgt_mmc0 {
				compatible = "hisilicon,clk-gate";
				#clock-cells = <0>;
				hiword;
				clocks = <&clk_gate_ppll0>;
				/*enable register, enable bit*/
				hisilicon,clkgate = <0xf4 2>;
				clock-output-names = "clkgt_mmc0";
			};

			clk_andgt_mmc1: clkgt_mmc1 {
				compatible = "hisilicon,clk-gate";
				#clock-cells = <0>;
				hiword;
				clocks = <&clk_gate_ppll0>;
				/*enable register, enable bit*/
				hisilicon,clkgate = <0xf4 3>;
				clock-output-names = "clkgt_mmc1";
			};

			clk_andgt_mmc2: clkgt_mmc2 {
				compatible = "hisilicon,clk-gate";
				#clock-cells = <0>;
				hiword;
				clocks = <&clk_gate_ppll0>;
				/*enable register, enable bit*/
				hisilicon,clkgate = <0xf4 4>;
				clock-output-names = "clkgt_mmc2";
			};

			clk_gate_mmc1peri2sysbus: clk_mmc12sysbus {
				compatible = "hisilicon,hi3630-clk-gate";
				#clock-cells = <0>;
				clocks = <&clk_div_sysbus>;
				hisilicon,hi3630-clkgate = <0x00 0x4000>;
				clock-output-names = "clk_mmc12sysbus";
			};

			clk_mmc1_peribus: clk_mmc1bus {
				compatible = "hisilicon,hi3630-clk-gate";
				#clock-cells = <0>;
				clocks = <&clk_div_mmc1_peribus>;
				hisilicon,hi3630-clkgate = <0x00 0x8000>;
				clock-output-names = "clk_mmc1bus";
			};

			clk_div_mmc0_peribus: clkdiv_mmc0bus {
				compatible = "hisilicon,hi3630-clk-div";
				#clock-cells = <0>;
				clocks = <&clk_div_sysbus>;
				hisilicon,clkdiv-table = <2 1>;
				hisilicon,clkdiv = <0xec 0x40>;
				clock-output-names = "clkdiv_mmc0bus";
			};

			clk_div_mmc1_peribus: clkdiv_mmc1bus {
				compatible = "hisilicon,hi3630-clk-div";
				#clock-cells = <0>;
				clocks = <&clk_div_sysbus>;
				hisilicon,clkdiv-table = <2 1>;
				hisilicon,clkdiv = <0xec 0x80>;
				clock-output-names = "clkdiv_mmc1bus";
			};

			/*follow timer clock to be another spare case*/
			pclk_timer4: pclk_timer4 {
				compatible = "hisilicon,hi3630-clk-gate";
				#clock-cells = <0>;
				clocks = <&clk_div_cfgbus>;
				hisilicon,hi3630-clkgate = <0x10 0x400000>;
				clock-output-names = "pclk_timer4";
			};

			pclk_timer5: pclk_timer5 {
				compatible = "hisilicon,hi3630-clk-gate";
				#clock-cells = <0>;
				clocks = <&clk_div_cfgbus>;
				hisilicon,hi3630-clkgate = <0x10 0x800000>;
				clock-output-names = "pclk_timer5";
			};

			pclk_timer6: pclk_timer6 {
				compatible = "hisilicon,hi3630-clk-gate";
				#clock-cells = <0>;
				clocks = <&clk_div_cfgbus>;
				hisilicon,hi3630-clkgate = <0x10 0x1000000>;
				clock-output-names = "pclk_timer6";
			};

			pclk_timer7: pclk_timer7 {
				compatible = "hisilicon,hi3630-clk-gate";
				#clock-cells = <0>;
				clocks = <&clk_div_cfgbus>;
				hisilicon,hi3630-clkgate = <0x10 0x2000000>;
				clock-output-names = "pclk_timer7";
			};

			/**/
			clk_gate_socp: clk_socp {
				compatible = "hisilicon,hi3630-clk-gate";
				#clock-cells = <0>;
				clocks = <&clk_div_dbgsechsic_bus>;
				hisilicon,hi3630-clkgate = <0x10 0x4000000>;
				clock-output-names = "clk_socp";
			};

			clk_gate_djtag: clk_gate_djtag {
				compatible = "hisilicon,hi3630-clk-gate";
				#clock-cells = <0>;
				clocks = <&clk_div_cfgbus>;
				hisilicon,hi3630-clkgate = <0x10 0x8000000>;
				clock-output-names = "clk_djtag";
			};

			clk_gate_pwm0: clk_pwm0 {
				compatible = "hisilicon,hi3630-clk-gate";
				#clock-cells = <0>;
				clocks = <&clk_div_cfgbus>;
				hisilicon,hi3630-clkgate = <0x20 0x1>;
				clock-output-names = "clk_pwm0";
			};

			clk_gate_pwm1: clk_pwm1 {
				compatible = "hisilicon,hi3630-clk-gate";
				#clock-cells = <0>;
				clocks = <&clk_div_cfgbus>;
				hisilicon,hi3630-clkgate = <0x20 0x2>;
				clock-output-names = "clk_pwm1";
			};

			pclk_gate_ipc0: pclk_ipc0 {
				compatible = "hisilicon,hi3630-clk-gate";
				#clock-cells = <0>;
				clocks = <&clk_div_cfgbus>;
				hisilicon,hi3630-clkgate = <0x20 0x4>;
				clock-output-names = "pclk_ipc0";
			};

			pclk_gate_ipc1: pclk_ipc1 {
				compatible = "hisilicon,hi3630-clk-gate";
				#clock-cells = <0>;
				clocks = <&clk_div_cfgbus>;
				hisilicon,hi3630-clkgate = <0x20 0x8>;
				clock-output-names = "pclk_ipc1";
			};

			pclk_gate_wd0_high: pclk_wd0_high {
				compatible = "hisilicon,hi3630-clk-gate";
				#clock-cells = <0>;
				clocks = <&clk_div_cfgbus>;
				hisilicon,hi3630-clkgate = <0x20 0x10000>;
				clock-output-names = "pclk_wd0_high";
			};

			pclk_gate_wd0: pclk_wd0 {
				compatible = "hisilicon,hi3630-clk-gate";
				#clock-cells = <0>;
				clocks = <&clk_mux_wd0>;
				/* <0x0 0x0> reprents the enable reg is fake */
				hisilicon,hi3630-clkgate = <0x0 0x0>;
				clock-output-names = "pclk_wd0";
			};

			clk_mux_wd0: clk_mux_wd0 {
				compatible = "hisilicon,hi3630-clk-mux";
				#clock-cells = <0>;
				clocks = <&clkin_ref &pclk_gate_wd0_high>;
				hisilicon,clkmux-reg = <0x140 0x20000>;
				clock-output-names = "clkmux_wd0";
			};

			pclk_gate_wd1: pclk_wd1 {
				compatible = "hisilicon,hi3630-clk-gate";
				#clock-cells = <0>;
				clocks = <&clk_div_cfgbus>;
				hisilicon,hi3630-clkgate = <0x20 0x20000>;
				clock-output-names = "pclk_wd1";
			};

			pclk_gate_tzpc: pclk_tzpc {
				compatible = "hisilicon,hi3630-clk-gate";
				#clock-cells = <0>;
				clocks = <&clk_div_cfgbus>;
				hisilicon,hi3630-clkgate = <0x20 0x40000>;
				clock-output-names = "pclk_tzpc";
			};

			clk_div_cfgbus: clkdiv_cfgbus {
				compatible = "hisilicon,hi3630-clk-div";
				#clock-cells = <0>;
				clocks = <&clk_div_sysbus>;
				hisilicon,clkdiv-table = <4 1>;
				hisilicon,clkdiv = <0xec 0x3>;
				clock-output-names = "clkdiv_cfgbus";
			};

			pclk_gate_tsi0: pclk_tsi0 {
				compatible = "hisilicon,hi3630-clk-gate";
				#clock-cells = <0>;
				clocks = <&pclk_div_tsi>;
				hisilicon,hi3630-clkgate = <0x20 0x80000>;
				clock-output-names = "pclk_tsi0";
			};

			pclk_gate_tsi1: pclk_tsi1 {
				compatible = "hisilicon,hi3630-clk-gate";
				#clock-cells = <0>;
				clocks = <&pclk_div_tsi>;
				hisilicon,hi3630-clkgate = <0x20 0x100000>;
				clock-output-names = "pclk_tsi1";
			};

			pclk_div_tsi: pclkdiv_tsi {
				compatible = "hisilicon,hi3630-clk-div";
				#clock-cells = <0>;
				clocks = <&clk_div_dmabus>;
				hisilicon,clkdiv-table = <4 1>;
				hisilicon,clkdiv = <0xd0 0x3000>;
				clock-output-names = "pclkdiv_tsi";
			};

			/**/
			clk_gate_gic: clk_gic {
				compatible = "hisilicon,hi3630-clk-gate";
				#clock-cells = <0>;
				clocks = <&clk_div_sysbus>;
				hisilicon,hi3630-clkgate = <0x20 0x800000>;
				clock-output-names = "clk_gic";
			};

			clk_gate_hkadcssi: clk_hkadcssi {
				compatible = "hisilicon,hi3630-clk-gate";
				#clock-cells = <0>;
				clocks = <&clk_div_cfgbus>;
				hisilicon,hi3630-clkgate = <0x20 0x1000000>;
				clock-output-names = "clk_hkadcssi";
			};

			clk_gate_codecssi: clk_codecssi {
				compatible = "hisilicon,hi3630-clk-gate";
				#clock-cells = <0>;
				clocks = <&clkin_sys>;
				hisilicon,hi3630-clkgate = <0x20 0x4000000>;
				clock-output-names = "clk_codecssi";
			};

			pclk_gate_pctrl: pclk_pctrl {
				compatible = "hisilicon,hi3630-clk-gate";
				#clock-cells = <0>;
				clocks = <&clkin_sys>;
				hisilicon,hi3630-clkgate = <0x20 0x80000000>;
				clock-output-names = "pclk_pctrl";
			};

			/**/
			clk_gate_dphy0: clk_dphy0{
				compatible = "hisilicon,hi3630-clk-gate";
				#clock-cells = <0>;
				clocks = <&clkin_sys>;
				hisilicon,hi3630-clkgate = <0x30 0x100000>;
				clock-output-names = "clk_dphy0";
			};

			clk_gate_dphy1: clk_dphy1{
				compatible = "hisilicon,hi3630-clk-gate";
				#clock-cells = <0>;
				clocks = <&clkin_sys>;
				hisilicon,hi3630-clkgate = <0x30 0x200000>;
				clock-output-names = "clk_dphy1";
			};

			clk_gate_dphy2: clk_dphy2{
				compatible = "hisilicon,hi3630-clk-gate";
				#clock-cells = <0>;
				clocks = <&clkin_sys>;
				hisilicon,hi3630-clkgate =  <0x30 0x400000>;
				clock-output-names = "clk_dphy2";
			};

			clk_gate_dphy3: clk_dphy3{
				compatible = "hisilicon,hi3630-clk-gate";
				#clock-cells = <0>;
				clocks = <&clkin_sys>;
				hisilicon,hi3630-clkgate = <0x30 0x4>;
				clock-output-names = "clk_dphy3";
			};

			/**/
			clk_gate_secp: clk_secp{
				compatible = "hisilicon,hi3630-clk-gate";
				#clock-cells = <0>;
				clocks = <&clk_div_dbgsechsic_bus>;
				hisilicon,hi3630-clkgate = <0x40 0x1000>;
				clock-output-names = "clk_secp";
			};

			clk_gate_dmatsibus: clk_dmatsibus{
				compatible = "hisilicon,hi3630-clk-gate";
				#clock-cells = <0>;
				clocks = <&pclk_div_tsi>;
				hisilicon,hi3630-clkgate = <0x50 0x1>;
				clock-output-names = "clk_dmatsibus";
			};

			/**/
			clk_gate_slimbus: clk_slimbus{
				compatible = "hisilicon,hi3630-clk-gate";
				#clock-cells = <0>;
				clocks = <&clk_div_slimbus>;
				hisilicon,hi3630-clkgate = <0x50 0x80>;
				clock-output-names = "clk_slimbus";
			};

			clk_div_slimbus: clkdiv_slimbus {
				compatible = "hisilicon,hi3630-clk-div";
				#clock-cells = <0>;
				clocks = <&clk_andgt_slimbus>;
				hisilicon,clkdiv-table = <64 1>;
				hisilicon,clkdiv = <0xd8 0x7e0>;
				clock-output-names = "clkdiv_slimbus";
			};

			clk_andgt_slimbus: clk_and_slimbus {
				compatible = "hisilicon,clk-gate";
				#clock-cells = <0>;
				hiword;
				clocks = <&clk_gate_ppll0>;
				/*enable register, enable bit*/
				hisilicon,clkgate = <0xf4 15>;
				clock-output-names = "clkgt_slimbus";
			};

			/**/
			clk_gate_jpeg: clk_jpeg {
				compatible = "hisilicon,hi3630-clk-gate";
				#clock-cells = <0>;
				clocks = <&clk_div_jpeg>;
				hisilicon,hi3630-clkgate = <0x50 0x10>;
				clock-output-names = "clk_jpeg";
			};

			clk_div_jpeg: clkdiv_jpeg {
				compatible = "hisilicon,hi3630-clk-div";
				#clock-cells = <0>;
				clocks = <&clk_andgt_jpeg>;
				hisilicon,clkdiv-table = <32 1>;
				hisilicon,clkdiv = <0xd4 0x1f>;
				clock-output-names = "clkdiv_jpeg";
			};

			clk_andgt_jpeg: clkgt_jpeg {
				compatible = "hisilicon,clk-gate";
				#clock-cells = <0>;
				hiword;
				clocks = <&clk_gate_ppll0>;
				/*enable register, enable bit*/
				hisilicon,clkgate = <0xf8 4>;
				clock-output-names = "clkgt_jpeg";
			};

			/**/
			clk_gate_memrep: clk_memrep {
				compatible = "hisilicon,hi3630-clk-gate";
				#clock-cells = <0>;
				clocks = <&clkin_sys>;
				hisilicon,hi3630-clkgate = <0x30 0x2000000>;
				clock-output-names = "clk_memrep";
			};

			/**/
			clk_gate_hsic: clk_hsic{
				compatible = "hisilicon,hi3630-clk-gate";
				#clock-cells = <0>;
				clocks = <&clk_div_hsic>;
				hisilicon,hi3630-clkgate = <0x40 0x400>;
				clock-output-names = "clk_hsic";
			};

			/**/
			clk_gate_cec: clk_cec{
				compatible = "hisilicon,hi3630-clk-gate";
				#clock-cells = <0>;
				clocks = <&clk_div_cec>;
				hisilicon,hi3630-clkgate = <0x30 0x80000>;
				clock-output-names = "clk_cec";
			};

			clk_div_cec: clkdiv_cec {
				compatible = "hisilicon,hi3630-clk-div";
				#clock-cells = <0>;
				clocks = <&clk_factor_usbhost12>;
				hisilicon,clkdiv-table = <8 1>;
				hisilicon,clkdiv = <0xc8 0xe000>;
				clock-output-names = "clkdiv_cec";
			};

			/**/
			pclk_gate_hdmi: pclk_hdmi{
				compatible = "hisilicon,hi3630-clk-gate";
				#clock-cells = <0>;
				clocks = <&pclk_div_hdmi>;
				hisilicon,hi3630-clkgate = <0x30 0x40000>;
				clock-output-names = "pclk_hdmi";
			};

			pclk_gate_hdmiefc: pclk_hdmiefc{
				compatible = "hisilicon,hi3630-clk-gate";
				#clock-cells = <0>;
				clocks = <&pclk_div_hdmi>;
				hisilicon,hi3630-clkgate = <0x30 0x20000000>;
				clock-output-names = "pclk_hdmiefc";
			};

			pclk_div_hdmi: pclkdiv_hdmi {
				compatible = "hisilicon,hi3630-clk-div";
				#clock-cells = <0>;
				clocks = <&pclk_andgt_hdmi>;
				hisilicon,clkdiv-table = <16 1>;
				hisilicon,clkdiv = <0xcc 0xf000>;
				clock-output-names = "pclkdiv_hdmi";
			};

			pclk_andgt_hdmi: pclkgt_hdmi {
				compatible = "hisilicon,clk-gate";
				#clock-cells = <0>;
				hiword;
				clocks = <&clk_div_hsic>;
				/*enable register, enable bit*/
				hisilicon,clkgate = <0xf4 14>;
				clock-output-names = "pclkgt_hdmi";
			};

			/**/
			pclk_gate_ioc: pclk_ioc {
				compatible = "hisilicon,hi3630-clk-gate";
				#clock-cells = <0>;
				clocks = <&clkin_sys>;
				hisilicon,hi3630-clkgate = <0x20 0x2000000>;
				clock-output-names = "pclk_ioc";
			};

			/**/
			clk_gate_noc_timeout_extref: clk_noc_timeout{
				compatible = "hisilicon,hi3630-clk-gate";
				#clock-cells = <0>;
				clocks = <&clkin_ref>;
				hisilicon,hi3630-clkgate = <0x50 0x8>;
				clock-output-names = "clk_noc_timeout";
			};

			/*bus*/
			clk_gate_vcodeccfg: clk_vcodeccfg {
				compatible = "hisilicon,hi3630-clk-gate";
				#clock-cells = <0>;
				clocks = <&clk_div_cfgbus>;
				hisilicon,hi3630-clkgate = <0x00 0x20>;
				clock-output-names = "clk_vcodeccfg";
			};

			clk_gate_sys2cfgbus: clk_sys2cfgbus {
				compatible = "hisilicon,hi3630-clk-gate";
				#clock-cells = <0>;
				clocks = <&clk_div_cfgbus>;
				hisilicon,hi3630-clkgate = <0x00 0x800>;
				clock-output-names = "clk_sys2cfgbus";
			};

			clk_gate_dbgsechsicbus: clk_dbgbus {
				compatible = "hisilicon,hi3630-clk-gate";
				#clock-cells = <0>;
				clocks = <&clk_div_dbgsechsic_bus>;
				hisilicon,hi3630-clkgate = <0x00 0x2000000>;
				clock-output-names = "clk_dbgbus";
			};

			clk_gate_dbgsechsic2sysbus: clk_dbg2sysbus {
				compatible = "hisilicon,hi3630-clk-gate";
				#clock-cells = <0>;
				clocks = <&clk_div_sysbus>;
				hisilicon,hi3630-clkgate = <0x00 0x4000000>;
				clock-output-names = "clk_dbg2sysbus";
			};

			clk_gate_vcodecbus: clk_vcodecbus{
				compatible = "hisilicon,hi3630-clk-gate";
				#clock-cells = <0>;
				clocks = <&fake_clk_parent>;
				hisilicon,hi3630-clkgate = <0x00 0x40>;
				clock-output-names = "clk_vcodecbus";
			};

			/*-------------------ORPHAN CLOCK-----------------------*/
			/*clk_gate_smmu: clk_smmu {
				compatible = "hisilicon,hi3630-clk-gate";
				#clock-cells = <0>;
				clocks = <&clk_div_smmu>;
				hisilicon,hi3630-clkgate = <0x040 0x100000>;
				clock-output-names = "clk_smmu";
			};*/

			/*clk_div_smmu: clkdiv_smmu {
				compatible = "hisilicon,hi3630-clk-div";
				#clock-cells = <0>;
				clocks = <&fake_clk_parent>;
				hisilicon,clkdiv-table = <4 1>;
				hisilicon,clkdiv = <0x0d0 0xc000>;
				clock-output-names = "clkdiv_smmu";
			};*/

			/*cclk_gate_smmu0: cclk_smmu0 {
				compatible = "hisilicon,hi3630-clk-gate";
				#clock-cells = <0>;
				clocks = <&fake_clk_parent>;
				hisilicon,hi3630-clkgate = <0x050 0x10000>;
				clock-output-names = "cclk_smmu0";
			};*/

			/*cclk_gate_smmu1: cclk_smmu1 {
				compatible = "hisilicon,hi3630-clk-gate";
				#clock-cells = <0>;
				clocks = <&fake_clk_parent>;
				hisilicon,hi3630-clkgate = <0x050 0x40000>;
				clock-output-names = "cclk_smmu1";
			};*/

			/*bclk_gate_smmu0: bclk_smmu0 {
				compatible = "hisilicon,hi3630-clk-gate";
				#clock-cells = <0>;
				clocks = <&fake_clk_parent>;
				hisilicon,hi3630-clkgate = <0x050 0x8000>;
				clock-output-names = "bclk_smmu0";
			};*/

			/*bclk_gate_smmu1: bclk_smmu1 {
				compatible = "hisilicon,hi3630-clk-gate";
				#clock-cells = <0>;
				clocks = <&fake_clk_parent>;
				hisilicon,hi3630-clkgate = <0x050 0x20000>;
				clock-output-names = "bclk_smmu1";
			};*/

			/*clk_gate_peri_hpm: clk_peri_hpm{
				compatible = "hisilicon,hi3630-clk-gate";
				#clock-cells = <0>;
				clocks = <&fake_clk_parent>;
				hisilicon,hi3630-clkgate = <0x050 0x1000>;
				clock-output-names = "clk_peri_hpm";
			};*/
		};
	};
};
